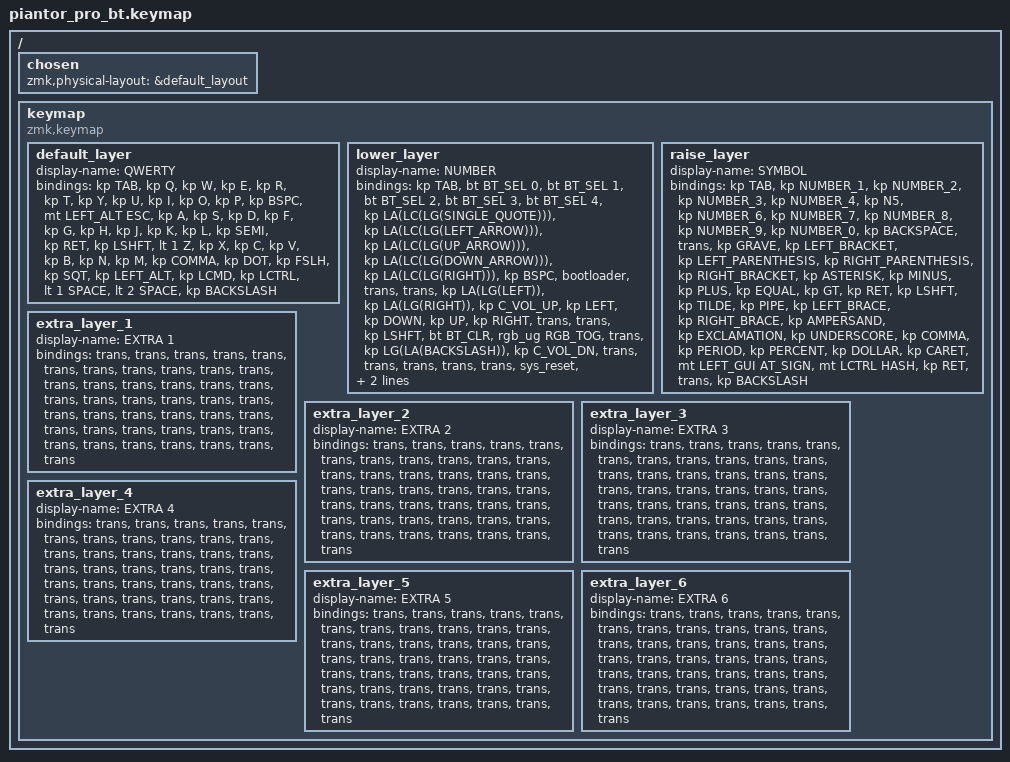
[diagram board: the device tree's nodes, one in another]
/*
 * Copyright (c) 2020 The ZMK Contributors
 *
 * SPDX-License-Identifier: MIT
 */

#include <behaviors.dtsi>
#include <dt-bindings/zmk/bt.h>
#include <dt-bindings/zmk/keys.h>
#include <dt-bindings/zmk/rgb.h>

/ {
    chosen { zmk,physical-layout = &default_layout; };
};

/ {
    keymap {
        compatible = "zmk,keymap";

        default_layer {
            display-name = "QWERTY";

            // --------------------------------------------------------------------------------
            // |  TAB |  Q  |  W  |  E  |  R  |  T  |  Y  |  U   |  I  |  O  |  P  | BSPC |
            // | CTRL |  A  |  S  |  D  |  F  |  G  |  H  |  J   |  K  |  L  |  ;  |  '   |
            // | SHFT |  Z  |  X  |  C  |  V  |  B  |  N  |  M   |  ,  |  .  |  /  | ESC  |
            //                    | GUI | LWR | SPC | ENT | RSE  | ALT |

            bindings = <
&kp TAB  &kp Q  &kp W  &kp E  &kp R  &kp T  &kp Y  &kp U  &kp I  &kp O  &kp P  &kp BSPC  &mt LEFT_ALT ESC  &kp A  &kp S  &kp D  &kp F  &kp G  &kp H  &kp J  &kp K  &kp L  &kp SEMI  &kp RET  &kp LSHFT  &lt 1 Z  &kp X  &kp C  &kp V  &kp B  &kp N  &kp M  &kp COMMA  &kp DOT  &kp FSLH  &kp SQT  &kp LEFT_ALT  &kp LCMD  &kp LCTRL  &lt 1 SPACE  &lt 2 SPACE  &kp BACKSLASH
            >;
        };

        lower_layer {
            display-name = "NUMBER";

            // -----------------------------------------------------------------------------------------
            // |  TAB |  1  |  2  |  3  |  4  |  5    |  6  |  7  |  8  |  9  |  0  | BSPC |
            // | CTRL | BT1 | BT2 | BT3 | BT4 | BT5   | LFT | DWN |  UP | RGT |     |      |
            // | SHFT | BTCR| RGB | RST | BOOT| Unlock|     |     |     |     |     |      |
            //                    | GUI |     | SPC   | ENT |     | ALT |

            bindings = <
&kp TAB  &bt BT_SEL 0  &bt BT_SEL 1  &bt BT_SEL 2  &bt BT_SEL 3  &bt BT_SEL 4  &kp LA(LC(LG(SINGLE_QUOTE)))  &kp LA(LC(LG(LEFT_ARROW)))  &kp LA(LC(LG(UP_ARROW)))  &kp LA(LC(LG(DOWN_ARROW)))  &kp LA(LC(LG(RIGHT)))  &kp BSPC  &bootloader  &trans  &trans  &kp LA(LG(LEFT))  &kp LA(LG(RIGHT))  &kp C_VOL_UP  &kp LEFT  &kp DOWN  &kp UP  &kp RIGHT  &trans  &trans  &kp LSHFT  &bt BT_CLR  &rgb_ug RGB_TOG  &trans  &kp LG(LA(BACKSLASH))  &kp C_VOL_DN  &trans  &trans  &trans  &trans  &trans  &sys_reset  &kp LGUI  &trans  &kp SPACE  &kp LGUI  &trans  &kp SPACE
            >;
        };

        raise_layer {
            display-name = "SYMBOL";

            // -----------------------------------------------------------------------------------------
            // |  TAB |  !  |  @  |  #  |  $  |  %  |  ^  |  &  |  *  |  (  |  )  | BSPC |
            // | CTRL | HUD | HUI |     |     |     |  -  |  =  |  [  |  ]  |  \  |  `   |
            // | SHFT |     |     |     |     |     |  _  |  +  |  {  |  }  | "|" |  ~   |
            //                    | GUI |     | SPC | ENT |     | ALT |

            bindings = <
&kp TAB  &kp NUMBER_1  &kp NUMBER_2  &kp NUMBER_3  &kp NUMBER_4  &kp N5  &kp NUMBER_6  &kp NUMBER_7  &kp NUMBER_8  &kp NUMBER_9  &kp NUMBER_0  &kp BACKSPACE  &trans  &kp GRAVE  &kp LEFT_BRACKET  &kp LEFT_PARENTHESIS  &kp RIGHT_PARENTHESIS  &kp RIGHT_BRACKET  &kp ASTERISK  &kp MINUS  &kp PLUS  &kp EQUAL  &kp GT  &kp RET  &kp LSHFT  &kp TILDE  &kp PIPE  &kp LEFT_BRACE  &kp RIGHT_BRACE  &kp AMPERSAND  &kp EXCLAMATION  &kp UNDERSCORE  &kp COMMA  &kp PERIOD  &kp PERCENT  &kp DOLLAR  &kp CARET  &mt LEFT_GUI AT_SIGN  &mt LCTRL HASH  &kp RET  &trans  &kp BACKSLASH
            >;
        };

        extra_layer_1 {
            display-name = "EXTRA 1";
            bindings = <
&trans  &trans  &trans  &trans  &trans  &trans  &trans  &trans  &trans  &trans  &trans  &trans  &trans  &trans  &trans  &trans  &trans  &trans  &trans  &trans  &trans  &trans  &trans  &trans  &trans  &trans  &trans  &trans  &trans  &trans  &trans  &trans  &trans  &trans  &trans  &trans  &trans  &trans  &trans  &trans  &trans  &trans
            >;
        };

        extra_layer_2 {
            display-name = "EXTRA 2";
            bindings = <
&trans  &trans  &trans  &trans  &trans  &trans  &trans  &trans  &trans  &trans  &trans  &trans  &trans  &trans  &trans  &trans  &trans  &trans  &trans  &trans  &trans  &trans  &trans  &trans  &trans  &trans  &trans  &trans  &trans  &trans  &trans  &trans  &trans  &trans  &trans  &trans  &trans  &trans  &trans  &trans  &trans  &trans
            >;
        };

        extra_layer_3 {
            display-name = "EXTRA 3";
            bindings = <
&trans  &trans  &trans  &trans  &trans  &trans  &trans  &trans  &trans  &trans  &trans  &trans  &trans  &trans  &trans  &trans  &trans  &trans  &trans  &trans  &trans  &trans  &trans  &trans  &trans  &trans  &trans  &trans  &trans  &trans  &trans  &trans  &trans  &trans  &trans  &trans  &trans  &trans  &trans  &trans  &trans  &trans
            >;
        };

        extra_layer_4 {
            display-name = "EXTRA 4";
            bindings = <
&trans  &trans  &trans  &trans  &trans  &trans  &trans  &trans  &trans  &trans  &trans  &trans  &trans  &trans  &trans  &trans  &trans  &trans  &trans  &trans  &trans  &trans  &trans  &trans  &trans  &trans  &trans  &trans  &trans  &trans  &trans  &trans  &trans  &trans  &trans  &trans  &trans  &trans  &trans  &trans  &trans  &trans
            >;
        };

        extra_layer_5 {
            display-name = "EXTRA 5";
            bindings = <
&trans  &trans  &trans  &trans  &trans  &trans  &trans  &trans  &trans  &trans  &trans  &trans  &trans  &trans  &trans  &trans  &trans  &trans  &trans  &trans  &trans  &trans  &trans  &trans  &trans  &trans  &trans  &trans  &trans  &trans  &trans  &trans  &trans  &trans  &trans  &trans  &trans  &trans  &trans  &trans  &trans  &trans
            >;
        };

        extra_layer_6 {
            display-name = "EXTRA 6";
            bindings = <
&trans  &trans  &trans  &trans  &trans  &trans  &trans  &trans  &trans  &trans  &trans  &trans  &trans  &trans  &trans  &trans  &trans  &trans  &trans  &trans  &trans  &trans  &trans  &trans  &trans  &trans  &trans  &trans  &trans  &trans  &trans  &trans  &trans  &trans  &trans  &trans  &trans  &trans  &trans  &trans  &trans  &trans
            >;
        };
    };
};
